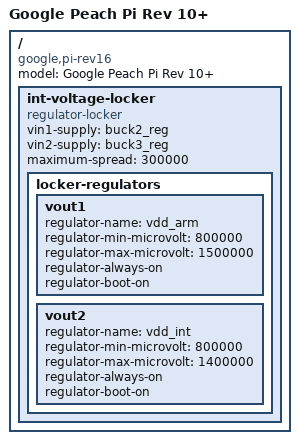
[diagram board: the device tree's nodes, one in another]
/*
 * Google Peach Pi Rev 10+ board device tree source
 *
 * Copyright (c) 2013 Google, Inc
 *
 * This program is free software; you can redistribute it and/or modify
 * it under the terms of the GNU General Public License version 2 as
 * published by the Free Software Foundation.
 */

/dts-v1/;
#include "exynos5422.dtsi"
#include "exynos542x-peach.dtsi"
#include "exynos542x-peach-pi.dtsi"
#include "cros-ec-keyboard.dtsi"

/ {
	model = "Google Peach Pi Rev 10+";

	compatible = "google,pi-rev16",
		"google,pi-rev15", "google,pi-rev14",
		"google,pi-rev13", "google,pi-rev12",
		"google,pi-rev11", "google,pi-rev10",
		"google,pi", "google,peach", "samsung,exynos5422";

	int-voltage-locker {
		compatible = "regulator-locker";
		vin1-supply = <&buck2_reg>; /* vdd_arm_real */
		vin2-supply = <&buck3_reg>; /* vdd_int_real */
		maximum-spread = <300000>;
		locker-regulators {
			vout1 {
				regulator-name = "vdd_arm";
				regulator-min-microvolt = <800000>;
				regulator-max-microvolt = <1500000>;
				regulator-always-on;
				regulator-boot-on;
			};
			vout2 {
				regulator-name = "vdd_int";
				regulator-min-microvolt = <800000>;
				regulator-max-microvolt = <1400000>;
				regulator-always-on;
				regulator-boot-on;
			};
		};
	};
};
